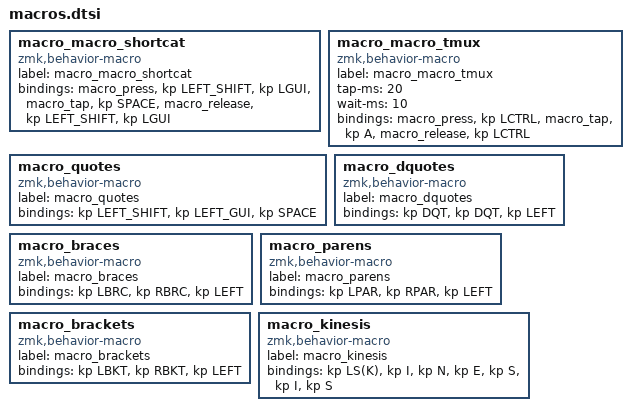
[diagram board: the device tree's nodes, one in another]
macro_macro_shortcat: macro_macro_shortcat{
compatible = "zmk,behavior-macro";
label = "macro_macro_shortcat";
#binding-cells = <0>;
bindings = <&macro_press &kp LEFT_SHIFT &kp LGUI>, <&macro_tap &kp SPACE>, <&macro_release &kp LEFT_SHIFT &kp LGUI>;
};
macro_macro_tmux: macro_macro_tmux{
compatible = "zmk,behavior-macro";
label = "macro_macro_tmux";
tap-ms = <20>;
wait-ms = <10>;
#binding-cells = <0>;
bindings = <&macro_press &kp LCTRL>, <&macro_tap &kp A>, <&macro_release &kp LCTRL>;
};
macro_quotes: macro_quotes{
compatible = "zmk,behavior-macro";
label = "macro_quotes";
#binding-cells = <0>;
bindings = <&kp LEFT_SHIFT>, <&kp LEFT_GUI>, <&kp SPACE>;
};
macro_dquotes: macro_dquotes{
compatible = "zmk,behavior-macro";
label = "macro_dquotes";
#binding-cells = <0>;
bindings = <&kp DQT>, <&kp DQT>, <&kp LEFT>;
};
macro_braces: macro_braces{
compatible = "zmk,behavior-macro";
label = "macro_braces";
#binding-cells = <0>;
bindings = <&kp LBRC>, <&kp RBRC>, <&kp LEFT>;
};
macro_parens: macro_parens{
compatible = "zmk,behavior-macro";
label = "macro_parens";
#binding-cells = <0>;
bindings = <&kp LPAR>, <&kp RPAR>, <&kp LEFT>;
};
macro_brackets: macro_brackets{
compatible = "zmk,behavior-macro";
label = "macro_brackets";
#binding-cells = <0>;
bindings = <&kp LBKT>, <&kp RBKT>, <&kp LEFT>;
};
macro_kinesis: macro_kinesis{
compatible = "zmk,behavior-macro";
label = "macro_kinesis";
#binding-cells = <0>;
bindings = <&kp LS(K)>, <&kp I>, <&kp N>, <&kp E>, <&kp S>, <&kp I>, <&kp S>;
};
